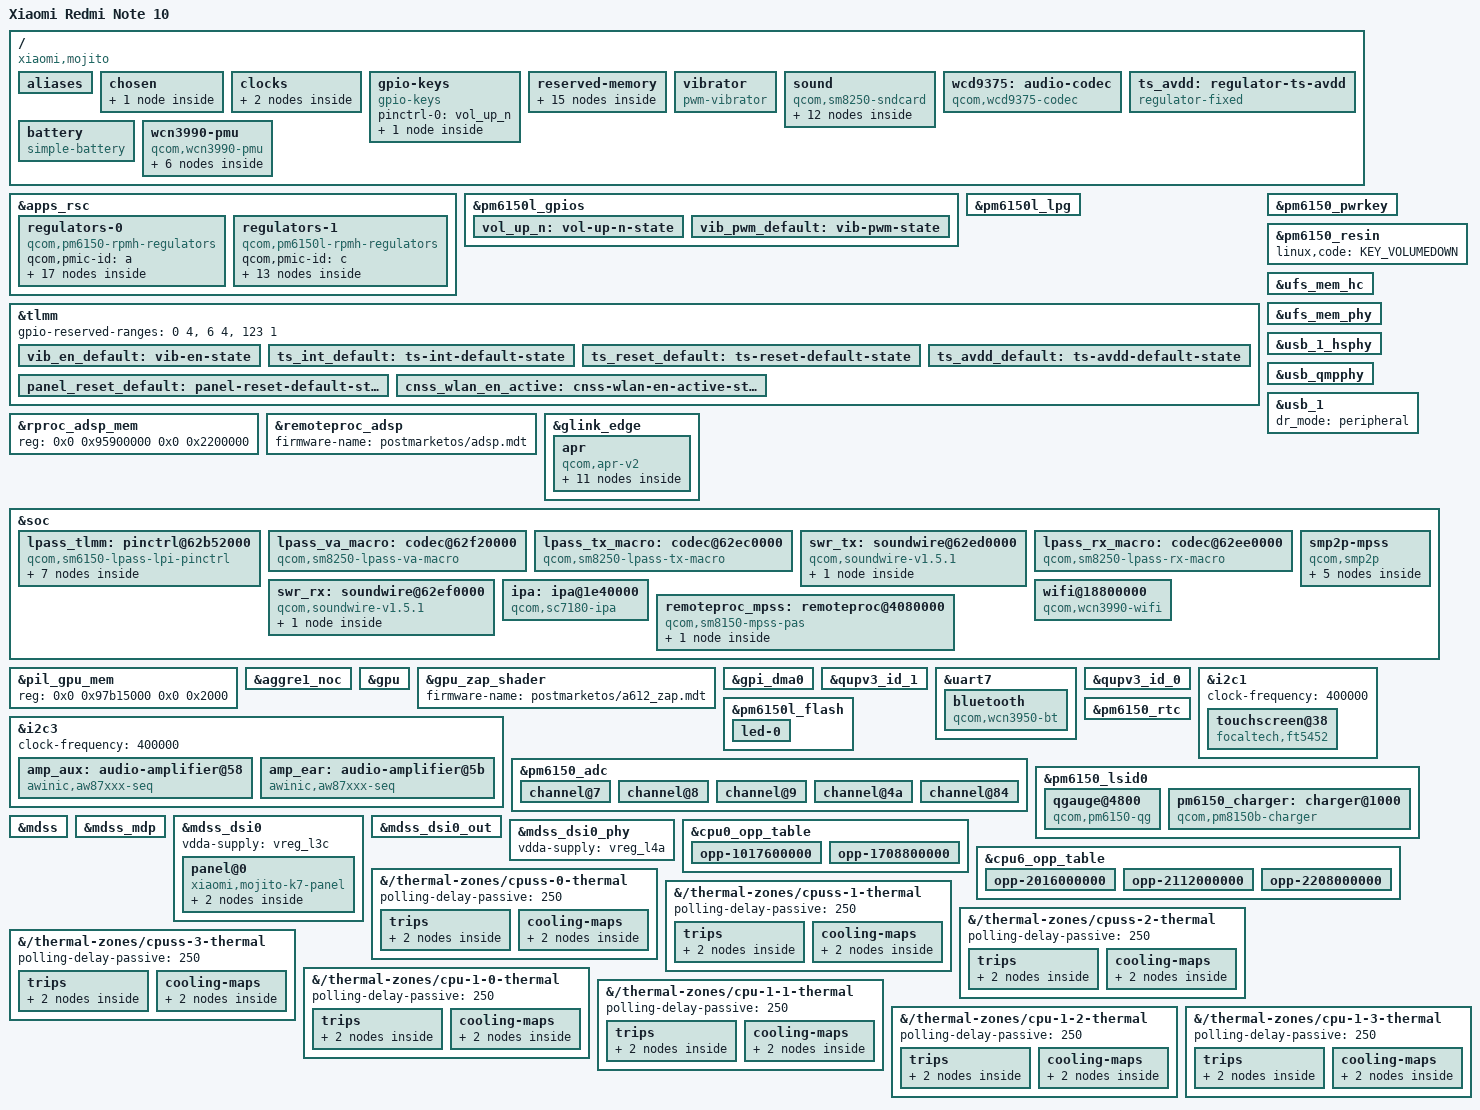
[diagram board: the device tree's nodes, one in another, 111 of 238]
// SPDX-License-Identifier: BSD-3-Clause
/*
 * Xiaomi Redmi Note 10 (mojito / sunny), SM6150 "Talos".
 *
 * Phase 1: boot to a shell. UFS root, USB peripheral (SSH over USB network),
 * buttons, and the bootloader's splash buffer as a simple-framebuffer.
 * Display (DSI panel), GPU, remoteprocs, touch and charging come later.
 *
 * Regulators, supplies and carveouts are taken from the stock downstream
 * device tree of this phone (MIUI V14.0.9.0.SKGMIXM).
 */

/dts-v1/;

#include <dt-bindings/gpio/gpio.h>
#include <dt-bindings/iio/qcom,spmi-vadc.h>
#include <dt-bindings/input/linux-event-codes.h>
#include <dt-bindings/leds/common.h>
#include <dt-bindings/pinctrl/qcom,pmic-gpio.h>
#include <dt-bindings/regulator/qcom,rpmh-regulator.h>
#include <dt-bindings/soc/qcom,apr.h>
#include <dt-bindings/sound/qcom,q6afe.h>
#include <dt-bindings/sound/qcom,q6asm.h>
#include "talos.dtsi"
#include "pm6150.dtsi"
#include "pm6150l.dtsi"

/ {
	model = "Xiaomi Redmi Note 10";
	compatible = "xiaomi,mojito", "qcom,sm6150";
	chassis-type = "handset";

	/*
	 * Matched by the Xiaomi bootloader (ABL) against the DTB in a boot image: msm-id as in the stock
	 * SM6150 DTB, board-id as in the stock IDP overlay. ABL refuses board-id <0 0>.
	 */
	qcom,msm-id = <0x163 0x0>;
	qcom,board-id = <0x22 0x0>;

	aliases {
		serial0 = &uart0;
		serial1 = &uart7;
	};

	chosen {
		#address-cells = <2>;
		#size-cells = <2>;
		ranges;

		/* The bootloader leaves the panel scanning out of cont_splash. */
		framebuffer0: framebuffer@9c000000 {
			compatible = "simple-framebuffer";
			reg = <0x0 0x9c000000 0x0 (1080 * 2400 * 4)>;
			memory-region = <&cont_splash_mem>;
			/*
			 * Deliberately NO power-domains and NO clocks here, although holding MDSS_CORE_GDSC and the display
			 * clocks keeps the splash alive until msm loads. The bootloader leaves its splash pipeline running and
			 * the DPU's CTL stuck in a hardware reset (it never accepts a frame: "hw recovery is not complete for
			 * ctl:1", blue screen); only a power cycle of the display core clears that, and holding the domain on
			 * means it is never cycled. Without the hold, genpd collapses MDSS_CORE_GDSC once nothing uses it
			 * and msm powers it up fresh, which works. Cost: a few seconds of green/black between the splash and
			 * the first real frame. An mdss "resets" line (DISP_CC_MDSS_CORE_BCR) hangs the phone at probe.
			 */
			width = <1080>;
			height = <2400>;
			stride = <(1080 * 4)>;
			format = "a8r8g8b8";
		};
	};

	clocks {
		/* Same SoC crystals as the QCS615 Ride (stock DT: chip_sleep_clk 32 kHz). */
		sleep_clk: sleep-clk {
			compatible = "fixed-clock";
			clock-frequency = <32000>;
			#clock-cells = <0>;
		};

		xo_board_clk: xo-board-clk {
			compatible = "fixed-clock";
			clock-frequency = <38400000>;
			#clock-cells = <0>;
		};
	};

	gpio-keys {
		compatible = "gpio-keys";
		pinctrl-0 = <&vol_up_n>;
		pinctrl-names = "default";

		key-volume-up {
			label = "Volume Up";
			gpios = <&pm6150l_gpios 2 GPIO_ACTIVE_LOW>;
			linux,code = <KEY_VOLUMEUP>;
			debounce-interval = <15>;
			linux,can-disable;
			wakeup-source;
		};
	};

	reserved-memory {
		/* Carveouts present in the stock DT but not (yet) in talos.dtsi. */
		hyp_mem: hyp@85700000 {
			reg = <0x0 0x85700000 0x0 0x600000>;
			no-map;
		};

		/* XBL/AOP firmware; aop-cmd-db@85f20000 (talos.dtsi) sits right after it. */
		xbl_aop_mem: xbl-aop@85e00000 {
			reg = <0x0 0x85e00000 0x0 0x120000>;
			no-map;
		};

		ipa_fw_mem: ipa-fw@97b00000 {
			reg = <0x0 0x97b00000 0x0 0x10000>;
			no-map;
		};

		ipa_gsi_mem: ipa-gsi@97b10000 {
			reg = <0x0 0x97b10000 0x0 0x5000>;
			no-map;
		};

		sec_apps_mem: sec-apps@85fff000 {
			reg = <0x0 0x85fff000 0x0 0x1000>;
			no-map;
		};

		removed_mem: removed@86200000 {
			reg = <0x0 0x86200000 0x0 0x4900000>;
			no-map;
		};

		camera_mem: camera@8ab00000 {
			reg = <0x0 0x8ab00000 0x0 0x500000>;
			no-map;
		};

		mpss_mem: mpss@8b000000 {
			reg = <0x0 0x8b000000 0x0 0x8400000>;
			no-map;
		};

		/* the whole stock wlan_msa_region (2 MB); ath10k assigns it to the modem and WLAN VMIDs itself, like stock icnss and the violet port */
		wlan_msa_mem: wlan-msa@93900000 {
			reg = <0x0 0x93900000 0x0 0x200000>;
			no-map;
		};

		/*
		 * rmtfs shared memory (modem file access through the rmtfs daemon). The vendor tree
		 * allocates it dynamically (qcom,sharedmem-uio reg = <0 0x280000>, guard memory), so this
		 * is a fixed, otherwise unused DRAM range above cdsp-sec (ends 0xa1600000), 0x280000 plus a
		 * guard page on each side. Same placement as the Redmi Note 7 Pro port.
		 */
		rmtfs_mem: rmtfs@a1dff000 {
			compatible = "qcom,rmtfs-mem";
			reg = <0x0 0xa1dff000 0x0 0x282000>;
			no-map;
			qcom,client-id = <1>;
			qcom,use-guard-pages;
			qcom,vmid = <QCOM_SCM_VMID_MSS_MSA>;
		};

		cont_splash_mem: cont-splash@9c000000 {
			reg = <0x0 0x9c000000 0x0 0xf00000>;
			no-map;
		};

		dfps_data_mem: dfps-data@9cf00000 {
			reg = <0x0 0x9cf00000 0x0 0x100000>;
			no-map;
		};

		ramoops@9d800000 {
			compatible = "ramoops";
			reg = <0x0 0x9d800000 0x0 0x400000>;
			/* same layout as the stock kernel, so either can read the other's log */
			record-size = <0x80000>;
			console-size = <0x100000>;
			pmsg-size = <0x200000>;
		};

		qseecom_mem: qseecom@9e400000 {
			reg = <0x0 0x9e400000 0x0 0x1400000>;
			no-map;
		};

		cdsp_sec_mem: cdsp-sec@9f800000 {
			reg = <0x0 0x9f800000 0x0 0x1e00000>;
			no-map;
		};
	};
};

&apps_rsc {
	regulators-0 {
		compatible = "qcom,pm6150-rpmh-regulators";
		qcom,pmic-id = "a";

		vreg_l1a: ldo1 {
			regulator-min-microvolt = <1200000>;
			regulator-max-microvolt = <1252000>;
			regulator-initial-mode = <RPMH_REGULATOR_MODE_HPM>;
		};

		vreg_l2a: ldo2 {
			regulator-min-microvolt = <1000000>;
			regulator-max-microvolt = <1050000>;
			regulator-initial-mode = <RPMH_REGULATOR_MODE_HPM>;
		};

		vreg_l3a: ldo3 {
			regulator-min-microvolt = <1000000>;
			regulator-max-microvolt = <1060000>;
			regulator-initial-mode = <RPMH_REGULATOR_MODE_HPM>;
		};

		vreg_l4a: ldo4 {
			regulator-min-microvolt = <875000>;
			regulator-max-microvolt = <975000>;
			regulator-initial-mode = <RPMH_REGULATOR_MODE_HPM>;
		};

		vreg_l5a: ldo5 {
			regulator-min-microvolt = <2500000>;
			regulator-max-microvolt = <2970000>;
			regulator-initial-mode = <RPMH_REGULATOR_MODE_HPM>;
		};

		vreg_l6a: ldo6 {
			regulator-min-microvolt = <600000>;
			regulator-max-microvolt = <650000>;
			regulator-initial-mode = <RPMH_REGULATOR_MODE_HPM>;
		};

		vreg_l9a: ldo9 {
			regulator-min-microvolt = <400000>;
			regulator-max-microvolt = <728000>;
			regulator-initial-mode = <RPMH_REGULATOR_MODE_HPM>;
		};

		/*
		 * 1.8 V I/O for the WCN3990 (Wi-Fi/Bluetooth), always on in the stock tree; nothing in
		 * Linux votes for it, and without it the WLFW host capability request fails (QMI 90).
		 */
		vreg_l10a: ldo10 {
			regulator-min-microvolt = <1800000>;
			regulator-max-microvolt = <1829000>;
			regulator-initial-mode = <RPMH_REGULATOR_MODE_HPM>;
		};

		vreg_l11a: ldo11 {
			regulator-min-microvolt = <1800000>;
			regulator-max-microvolt = <1890000>;
			regulator-initial-mode = <RPMH_REGULATOR_MODE_HPM>;
		};

		vreg_l12a: ldo12 {
			regulator-min-microvolt = <1800000>;
			regulator-max-microvolt = <1950000>;
			regulator-initial-mode = <RPMH_REGULATOR_MODE_HPM>;
		};

		vreg_l13a: ldo13 {
			regulator-min-microvolt = <1800000>;
			regulator-max-microvolt = <1900000>;
			regulator-initial-mode = <RPMH_REGULATOR_MODE_HPM>;
		};

		vreg_l14a: ldo14 {
			regulator-min-microvolt = <1800000>;
			regulator-max-microvolt = <1850000>;
			regulator-initial-mode = <RPMH_REGULATOR_MODE_HPM>;
		};

		vreg_l15a: ldo15 {
			regulator-min-microvolt = <1800000>;
			regulator-max-microvolt = <1900000>;
			regulator-initial-mode = <RPMH_REGULATOR_MODE_HPM>;
		};

		vreg_l16a: ldo16 {
			regulator-min-microvolt = <2430000>;
			regulator-max-microvolt = <2970000>;
			regulator-initial-mode = <RPMH_REGULATOR_MODE_HPM>;
		};

		vreg_l17a: ldo17 {
			regulator-min-microvolt = <3000000>;
			regulator-max-microvolt = <3230000>;
			regulator-initial-mode = <RPMH_REGULATOR_MODE_HPM>;
		};

		vreg_l18a: ldo18 {
			regulator-min-microvolt = <3000000>;
			regulator-max-microvolt = <3008000>;
			regulator-initial-mode = <RPMH_REGULATOR_MODE_HPM>;
		};

		vreg_l19a: ldo19 {
			regulator-min-microvolt = <2700000>;
			regulator-max-microvolt = <3008000>;
			regulator-initial-mode = <RPMH_REGULATOR_MODE_HPM>;
		};
	};

	regulators-1 {
		compatible = "qcom,pm6150l-rpmh-regulators";
		qcom,pmic-id = "c";

		/* WCD937x mic bias (stock: cdc-vdd-mic-bias-supply = pm6150l_bob) */
		vreg_bob: bob {
			regulator-min-microvolt = <3296000>;
			regulator-max-microvolt = <3960000>;
			regulator-initial-mode = <RPMH_REGULATOR_MODE_AUTO>;
		};

		vreg_s8c: smps8 {
			regulator-min-microvolt = <1200000>;
			regulator-max-microvolt = <1400000>;
			regulator-initial-mode = <RPMH_REGULATOR_MODE_HPM>;
		};

		vreg_l1c: ldo1 {
			regulator-min-microvolt = <1800000>;
			regulator-max-microvolt = <1900000>;
			regulator-initial-mode = <RPMH_REGULATOR_MODE_HPM>;
		};

		vreg_l2c: ldo2 {
			regulator-min-microvolt = <1304000>;
			regulator-max-microvolt = <1304000>;
			regulator-initial-mode = <RPMH_REGULATOR_MODE_HPM>;
		};

		vreg_l3c: ldo3 {
			regulator-min-microvolt = <1232000>;
			regulator-max-microvolt = <1260000>;
			regulator-initial-mode = <RPMH_REGULATOR_MODE_HPM>;
		};

		vreg_l4c: ldo4 {
			regulator-min-microvolt = <1650000>;
			regulator-max-microvolt = <2950000>;
			regulator-initial-mode = <RPMH_REGULATOR_MODE_HPM>;
		};

		vreg_l5c: ldo5 {
			regulator-min-microvolt = <1650000>;
			regulator-max-microvolt = <2950000>;
			regulator-initial-mode = <RPMH_REGULATOR_MODE_HPM>;
		};

		vreg_l6c: ldo6 {
			regulator-min-microvolt = <1650000>;
			regulator-max-microvolt = <3100000>;
			regulator-initial-mode = <RPMH_REGULATOR_MODE_HPM>;
		};

		vreg_l7c: ldo7 {
			regulator-min-microvolt = <3000000>;
			regulator-max-microvolt = <3312000>;
			regulator-initial-mode = <RPMH_REGULATOR_MODE_HPM>;
		};

		vreg_l8c: ldo8 {
			regulator-min-microvolt = <1800000>;
			regulator-max-microvolt = <1900000>;
			regulator-initial-mode = <RPMH_REGULATOR_MODE_HPM>;
		};

		vreg_l9c: ldo9 {
			regulator-min-microvolt = <2950000>;
			regulator-max-microvolt = <3312000>;
			regulator-initial-mode = <RPMH_REGULATOR_MODE_HPM>;
		};

		vreg_l10c: ldo10 {
			regulator-min-microvolt = <3200000>;
			regulator-max-microvolt = <3312000>;
			regulator-initial-mode = <RPMH_REGULATOR_MODE_HPM>;
		};

		vreg_l11c: ldo11 {
			regulator-min-microvolt = <2950000>;
			regulator-max-microvolt = <3312000>;
			regulator-initial-mode = <RPMH_REGULATOR_MODE_HPM>;
		};
	};
};

/* stock: the volume-up key and the vibrator PWM are on the PM6150L, not the PM6150 */
&pm6150l_gpios {
	vol_up_n: vol-up-n-state {
		pins = "gpio2";
		function = "normal";
		power-source = <0>;
		bias-pull-up;
		input-enable;
	};

	vib_pwm_default: vib-pwm-state {
		pins = "gpio6";
		function = "func1";
		power-source = <0>;
		qcom,drive-strength = <3>;
		drive-push-pull;
		bias-disable;
		output-low;
	};
};

/* PWM channel at SPMI 0xbc00 (index 3) drives the vibration motor */
&pm6150l_lpg {
	status = "okay";
};

&tlmm {
	vib_en_default: vib-en-state {
		pins = "gpio112";
		function = "gpio";
		drive-strength = <2>;
		bias-disable;
		output-low;
	};
};

/ {
	/* stock "qcom,lct-pwm-vibrator": 50 us period, enable on TLMM 112 */
	vibrator {
		compatible = "pwm-vibrator";
		pinctrl-names = "default";
		pinctrl-0 = <&vib_en_default>, <&vib_pwm_default>;
		pwms = <&pm6150l_lpg 3 50000>;
		pwm-names = "enable";
		enable-gpios = <&tlmm 112 GPIO_ACTIVE_HIGH>;
	};
};

&pm6150_pwrkey {
	status = "okay";
};

&pm6150_resin {
	linux,code = <KEY_VOLUMEDOWN>;
	status = "okay";
};


&ufs_mem_hc {
	vcc-supply = <&vreg_l11c>;
	vcc-max-microamp = <600000>;
	vccq2-supply = <&vreg_l12a>;
	vccq2-max-microamp = <600000>;

	status = "okay";
};

&ufs_mem_phy {
	vdda-phy-supply = <&vreg_l4a>;
	vdda-pll-supply = <&vreg_l11a>;

	status = "okay";
};

&usb_1_hsphy {
	vdd-supply = <&vreg_l4a>;
	vdda-pll-supply = <&vreg_l11a>;
	vdda-phy-dpdm-supply = <&vreg_l17a>;

	status = "okay";
};

&usb_qmpphy {
	vdda-phy-supply = <&vreg_l4a>;
	vdda-pll-supply = <&vreg_l11a>;

	status = "okay";
};

&usb_1 {
	/* No Type-C role switching yet: stay a USB gadget for SSH over USB. */
	dr_mode = "peripheral";

	status = "okay";
};

/* Xiaomi's firmware layout differs from the QCS615 Ride's. */
&rproc_adsp_mem {
	reg = <0x0 0x95900000 0x0 0x2200000>;
};

/*
 * ADSP (audio, sensors). Stock firmware from the phone's modem partition, signed for this device.
 * It speaks legacy APR, not AudioReach, so talos.dtsi's gpr/q6apm children stay unused (the
 * firmware never opens "adsp_apps"); APR nodes come with the sound card.
 */
&remoteproc_adsp {
	firmware-name = "postmarketos/adsp.mdt";
	status = "okay";
};

/*
 * Audio services on the ADSP: legacy APR (the firmware offers "apr_audio_svc"), replacing talos.dtsi's
 * AudioReach gpr node, which this firmware never answers. Layout as in the Redmi Note 7 Pro port, with
 * the protection domains declared (pd-mapper works here, patch 0011). ASM shared memory goes through
 * SMMU stream 0x1721 (stock msm_audio_ion), which needs patch 0014 (hypervisor-owned context banks).
 */
/delete-node/ &gpr;

&glink_edge {
	apr {
		compatible = "qcom,apr-v2";
		qcom,glink-channels = "apr_audio_svc";
		qcom,domain = <APR_DOMAIN_ADSP>;
		#address-cells = <1>;
		#size-cells = <0>;

		service@3 {
			compatible = "qcom,q6core";
			reg = <APR_SVC_ADSP_CORE>;
			qcom,protection-domain = "avs/audio", "msm/adsp/audio_pd";
		};

		q6afe: service@4 {
			compatible = "qcom,q6afe";
			reg = <APR_SVC_AFE>;
			qcom,protection-domain = "avs/audio", "msm/adsp/audio_pd";

			q6afedai: dais {
				compatible = "qcom,q6afe-dais";
				#address-cells = <1>;
				#size-cells = <0>;
				#sound-dai-cells = <1>;
			};

			q6afecc: clock-controller {
				compatible = "qcom,q6afe-clocks";
				#clock-cells = <2>;
			};
		};

		q6asm: service@7 {
			compatible = "qcom,q6asm";
			reg = <APR_SVC_ASM>;
			qcom,protection-domain = "avs/audio", "msm/adsp/audio_pd";

			q6asmdai: dais {
				compatible = "qcom,q6asm-dais";
				#address-cells = <1>;
				#size-cells = <0>;
				#sound-dai-cells = <1>;
				iommus = <&apps_smmu 0x1721 0x0>;

				dai@0 {
					reg = <MSM_FRONTEND_DAI_MULTIMEDIA1>;
				};

				dai@1 {
					reg = <MSM_FRONTEND_DAI_MULTIMEDIA2>;
				};

				dai@2 {
					reg = <MSM_FRONTEND_DAI_MULTIMEDIA3>;
				};
			};
		};

		q6adm: service@8 {
			compatible = "qcom,q6adm";
			reg = <APR_SVC_ADM>;
			qcom,protection-domain = "avs/audio", "msm/adsp/audio_pd";

			q6routing: routing {
				compatible = "qcom,q6adm-routing";
				#sound-dai-cells = <0>;
			};
		};
	};
};

/*
 * Audio: LPASS LPI pins + VA/TX/RX macros + SoundWire + WCD9375 (stock "bolero" layout).
 * Sources: stock mojito DT (pins, IRQs, supplies, mic bias), the SM7150 ports that have the same LPASS
 * block and codec (Xiaomi surya / Mi 9T fixes: LPI mux, reset pin as gpio, no dcodec vote, TX port map),
 * and the violet notes (APR, not AudioReach). Untested on this phone (2026-11-27).
 */
&soc {
	/* stock lpi_pinctrl: 0x62b40000 + 0x1000 per pin, gpio18..31 = these pins 0..13 */
	lpass_tlmm: pinctrl@62b52000 {
		compatible = "qcom,sm6150-lpass-lpi-pinctrl";
		reg = <0x0 0x62b52000 0x0 0xe000>;
		/* stock: lpass_core_hw_vote (audio-ref-clk src 9) = AFE LPASS core HW vote */
		clocks = <&q6afecc LPASS_HW_MACRO_VOTE LPASS_CLK_ATTRIBUTE_COUPLE_NO>;
		clock-names = "core";
		gpio-controller;
		#gpio-cells = <2>;
		gpio-ranges = <&lpass_tlmm 0 0 14>;

		tx_swr_active: tx-swr-active-state {
			clk-pins {
				pins = "gpio0";
				function = "swr_tx_clk";
				drive-strength = <8>;
				bias-bus-hold;
			};

			data-pins {
				pins = "gpio1", "gpio2";
				function = "swr_tx_data";
				drive-strength = <8>;
				bias-bus-hold;
			};
		};

		rx_swr_active: rx-swr-active-state {
			clk-pins {
				pins = "gpio3";
				function = "swr_rx_clk";
				drive-strength = <8>;
				bias-bus-hold;
			};

			data-pins {
				pins = "gpio4", "gpio5";
				function = "swr_rx_data";
				drive-strength = <8>;
				bias-bus-hold;
			};
		};

		/* stock msm_cdc_pinctrl@24 (qcom,lpi-gpios): WCD937x reset; plain gpio, level owned by the driver */
		wcd_reset_default: wcd-reset-default-state {
			pins = "gpio6";
			function = "gpio";
			drive-strength = <16>;
			bias-disable;
		};
	};

	/* fsgen master for TX/RX; shares the TX core mclk; only the "macro" vote (no dcodec in this firmware) */
	lpass_va_macro: codec@62f20000 {
		compatible = "qcom,sm8250-lpass-va-macro";
		reg = <0x0 0x62f20000 0x0 0x1000>;
		clocks = <&q6afecc LPASS_CLK_ID_TX_CORE_MCLK LPASS_CLK_ATTRIBUTE_COUPLE_NO>,
			 <&q6afecc LPASS_HW_MACRO_VOTE LPASS_CLK_ATTRIBUTE_COUPLE_NO>;
		clock-names = "mclk", "macro";
		#clock-cells = <0>;
		clock-output-names = "fsgen";
		#sound-dai-cells = <1>;
	};

	lpass_tx_macro: codec@62ec0000 {
		compatible = "qcom,sm8250-lpass-tx-macro";
		reg = <0x0 0x62ec0000 0x0 0x1000>;
		pinctrl-names = "default";
		pinctrl-0 = <&tx_swr_active>;
		clocks = <&q6afecc LPASS_CLK_ID_TX_CORE_MCLK LPASS_CLK_ATTRIBUTE_COUPLE_NO>,
			 <&q6afecc LPASS_CLK_ID_TX_CORE_NPL_MCLK LPASS_CLK_ATTRIBUTE_COUPLE_NO>,
			 <&q6afecc LPASS_HW_MACRO_VOTE LPASS_CLK_ATTRIBUTE_COUPLE_NO>,
			 <&lpass_va_macro>;
		clock-names = "mclk", "npl", "macro", "fsgen";
		#clock-cells = <0>;
		clock-output-names = "lpass-tx-mclk";
		#sound-dai-cells = <1>;
	};

	/* stock tx_swr_master: swrm-io-base 0x62ed0000, SPI 137 + wake SPI 623 (= PDC pin 108) */
	swr_tx: soundwire@62ed0000 {
		compatible = "qcom,soundwire-v1.5.1";
		reg = <0x0 0x62ed0000 0x0 0x2000>;
		interrupts-extended = <&intc GIC_SPI 137 IRQ_TYPE_LEVEL_HIGH 0>,
				      <&pdc 108 IRQ_TYPE_LEVEL_HIGH>;
		interrupt-names = "core", "wakeup";
		clocks = <&lpass_tx_macro>;
		clock-names = "iface";
		label = "TX";

		/* hardware: 6 in + 1 out (port 1 = PCM_OUT1); one byte per port, 7 ports.
		 * Timing = stock tx_frame_params_superset (si 3, lane 0); the SM7150 "perf" values gave zeros. */
		qcom,din-ports = <6>;
		qcom,dout-ports = <1>;
		qcom,ports-sinterval-low =	/bits/ 8 <0xff 0x03 0x03 0x03 0x03 0xff 0xff>;
		qcom,ports-offset1 =		/bits/ 8 <0xff 0x01 0x02 0x01 0x00 0xff 0xff>;
		qcom,ports-offset2 =		/bits/ 8 <0xff 0x00 0x00 0x00 0x00 0xff 0xff>;
		qcom,ports-block-pack-mode =	/bits/ 8 <0xff 0xff 0xff 0xff 0xff 0xff 0xff>;
		qcom,ports-hstart =		/bits/ 8 <0xff 0xff 0xff 0xff 0xff 0xff 0xff>;
		qcom,ports-hstop =		/bits/ 8 <0xff 0xff 0xff 0xff 0xff 0xff 0xff>;
		qcom,ports-word-length =	/bits/ 8 <0xff 0xff 0xff 0xff 0xff 0xff 0xff>;
		qcom,ports-block-group-count =	/bits/ 8 <0xff 0xff 0xff 0xff 0xff 0xff 0xff>;
		qcom,ports-lane-control =	/bits/ 8 <0xff 0x00 0x00 0x00 0x00 0xff 0xff>;

		#sound-dai-cells = <1>;
		#address-cells = <2>;
		#size-cells = <0>;

		wcd_tx: codec@0,3 {
			compatible = "sdw20217010a00";
			reg = <0 3>;
			/* WCD937x TX ports ADC1, ADC2/3, DMIC0-3+MBHC, DMIC4-7 -> SWR ports 2, 2, 3, 4 (port 1 = PCM_OUT1) */
			qcom,tx-port-mapping = <2 2 3 4>;
		};
	};

	lpass_rx_macro: codec@62ee0000 {
		compatible = "qcom,sm8250-lpass-rx-macro";
		reg = <0x0 0x62ee0000 0x0 0x1000>;
		pinctrl-names = "default";
		pinctrl-0 = <&rx_swr_active>;
		clocks = <&q6afecc LPASS_CLK_ID_RX_CORE_MCLK LPASS_CLK_ATTRIBUTE_COUPLE_NO>,
			 <&q6afecc LPASS_CLK_ID_RX_CORE_NPL_MCLK LPASS_CLK_ATTRIBUTE_COUPLE_NO>,
			 <&q6afecc LPASS_HW_MACRO_VOTE LPASS_CLK_ATTRIBUTE_COUPLE_NO>,
			 <&lpass_va_macro>;
		clock-names = "mclk", "npl", "macro", "fsgen";
		#clock-cells = <0>;
		clock-output-names = "lpass-rx-mclk";
		#sound-dai-cells = <1>;
	};

	/* stock rx_swr_master: 0x62ef0000, SPI 138 */
	swr_rx: soundwire@62ef0000 {
		compatible = "qcom,soundwire-v1.5.1";
		reg = <0x0 0x62ef0000 0x0 0x2000>;
		interrupts = <GIC_SPI 138 IRQ_TYPE_LEVEL_HIGH 0>;
		clocks = <&lpass_rx_macro>;
		clock-names = "iface";
		label = "RX";

		/* hardware: 1 in + 6 out; one byte per port, 7 ports (short tables clash the bus) */
		qcom,din-ports = <1>;
		qcom,dout-ports = <6>;
		qcom,ports-sinterval-low =	/bits/ 8 <0x03 0x1f 0x1f 0x07 0x00 0xff 0xff>;
		qcom,ports-offset1 =		/bits/ 8 <0x00 0x00 0x0b 0x01 0x00 0xff 0xff>;
		qcom,ports-offset2 =		/bits/ 8 <0x00 0x00 0x0b 0x00 0x00 0xff 0xff>;
		qcom,ports-hstart =		/bits/ 8 <0xff 0x03 0xff 0xff 0xff 0xff 0xff>;
		qcom,ports-hstop =		/bits/ 8 <0xff 0x06 0xff 0xff 0xff 0xff 0xff>;
		qcom,ports-word-length =	/bits/ 8 <0x01 0x07 0x04 0xff 0xff 0xff 0xff>;
		qcom,ports-block-pack-mode =	/bits/ 8 <0xff 0x00 0x01 0xff 0xff 0xff 0xff>;
		qcom,ports-lane-control =	/bits/ 8 <0x01 0x00 0x00 0x00 0x00 0xff 0xff>;
		qcom,ports-block-group-count =	/bits/ 8 <0xff 0xff 0xff 0xff 0x00 0xff 0xff>;

		#sound-dai-cells = <1>;
		#address-cells = <2>;
		#size-cells = <0>;

		wcd_rx: codec@0,4 {
			compatible = "sdw20217010a00";
			reg = <0 4>;
			qcom,rx-port-mapping = <1 2 3 4 5>;
		};
	};


};

/ {
	sound {
		compatible = "qcom,sm8250-sndcard";
		model = "Xiaomi Redmi Note 10";

		/* stock mics: amic1 = ADC1 (main), amic2/amic3 = ADC2 via ADC2 MUX INP2/INP3 */
		aux-devs = <&amp_aux>, <&amp_ear>;

		audio-routing =
			"AUX Amp IN", "AUX",
			"EAR Amp IN", "EAR",
			"AMIC1", "MIC BIAS1",
			"AMIC2", "MIC BIAS2",
			"AMIC3", "MIC BIAS3",
			"TX SWR_ADC0", "ADC1_OUTPUT",
			"TX SWR_ADC1", "ADC2_OUTPUT",
			"TX SWR_ADC2", "ADC3_OUTPUT";

		mm1-dai-link {
			link-name = "MultiMedia1";

			cpu {
				sound-dai = <&q6asmdai MSM_FRONTEND_DAI_MULTIMEDIA1>;
			};
		};

		mm2-dai-link {
			link-name = "MultiMedia2";

			cpu {
				sound-dai = <&q6asmdai MSM_FRONTEND_DAI_MULTIMEDIA2>;
			};
		};

		/* headphones (and earpiece/speaker later, via WCD937x EAR/AUX + the AW87xxx amps) */
		wcd-playback-dai-link {
			link-name = "WCD Playback";

			cpu {
				sound-dai = <&q6afedai RX_CODEC_DMA_RX_0>;
			};

			platform {
				sound-dai = <&q6routing>;
			};

			codec {
				sound-dai = <&wcd9375 0>, <&swr_rx 0>, <&lpass_rx_macro 0>;
			};
		};

		wcd-capture-dai-link {
			link-name = "WCD Capture";

			cpu {
				sound-dai = <&q6afedai TX_CODEC_DMA_TX_3>;
			};

			platform {
				sound-dai = <&q6routing>;
			};

			codec {
				/* swr_tx has one dout port, so DAI 0 is playback-only; capture DAIs start at 1.
				 * With DAI 0 no master data port is set up and the mic records zeros. */
				sound-dai = <&wcd9375 1>, <&swr_tx 1>, <&lpass_tx_macro 0>;
			};
		};
	};
	wcd9375: audio-codec {
		compatible = "qcom,wcd9375-codec";
		pinctrl-names = "default";
		pinctrl-0 = <&wcd_reset_default>;
		reset-gpios = <&lpass_tlmm 6 GPIO_ACTIVE_LOW>;

		/* stock: buck = pm6150_l15, rxtx/px = pm6150_l10, mic bias = pm6150l_bob, micbias 2.7 V */
		vdd-buck-supply = <&vreg_l15a>;
		vdd-rxtx-supply = <&vreg_l10a>;
		vdd-px-supply = <&vreg_l10a>;
		vdd-mic-bias-supply = <&vreg_bob>;

		qcom,micbias1-microvolt = <2700000>;
		qcom,micbias2-microvolt = <2700000>;
		qcom,micbias3-microvolt = <2700000>;
		qcom,micbias4-microvolt = <2700000>;

		qcom,rx-device = <&wcd_rx>;
		qcom,tx-device = <&wcd_tx>;

		#sound-dai-cells = <1>;
	};
};

&pil_gpu_mem {
	reg = <0x0 0x97b15000 0x0 0x2000>;
};

/*
 * Hardware hazards found on this SoC family. Both were also hit by the Redmi Note 7 Pro port
 * (github.com/VipinVIP/violet-sm6150-mainline); the TLMM one needs more reservations on this phone.
 */

/*
 * TLMM: eight GPIOs are owned by the secure world and must not be read: gpio0-3 (WEST tile) and gpio6-9
 * (EAST tile), probably the first two QUP serial engines kept for something like a fingerprint sensor or a
 * secure element. A read of gpio0 or gpio1 hangs the CPU; a read of gpio2, 3 or 6-9 raises a synchronous
 * external abort. The pin controller reads the control register of every valid line when it registers the
 * gpio chip, so a single one of these being valid kills the probe (the oops is in msm_gpio_get_direction).
 *
 * Found by reading every pin through /dev/mem from userspace, one child process per pin, and recording the
 * child's exit status (a child killed by SIGBUS is an abort, a child that never returns is a wedge); the
 * other 115 pins read back plausible register values, and the kernel then registered the chip and dumped all
 * of them. The Redmi Note 7 Pro port reserves only <0 4>, which is not enough here (gpio6 aborts).
 *
 * gpio123 is UFS_RESET (its register is at west tile + 0x9f000, outside the 0x1000 * id pattern); it was
 * not scanned and nothing here uses it, so it stays reserved as a precaution.
 */
&tlmm {
	gpio-reserved-ranges = <0 4>, <6 4>, <123 1>;
};

/* aggre1_noc QoS writes hang the CPU: leave it unclocked so they are skipped. */
&aggre1_noc {
	/delete-property/ clocks;
};

/*
 * Adreno 612. Needs msm.ko loaded with separate_gpu_kms=1 while no display subsystem is enabled (the
 * display stays on simpledrm), which gives a render-only DRM device. Firmware: a630_sqe.fw and a612_rgmu.bin
 * are found through /lib/firmware/qcom (symlinks to /lib/firmware/postmarketos/, left by the downstream
 * install). The zap shader is signed for this phone by the vendor, so it must come from the stock firmware:
 * the split a612_zap.mdt + .b00-.b02 already in /lib/firmware/postmarketos/.
 */
&gpu {
	status = "okay";
};

&gpu_zap_shader {
	firmware-name = "postmarketos/a612_zap.mdt";
};

/*
 * Touchscreen: FocalTech FT5452 on i2c1 (QUP0 SE1, gpio4/gpio5) at 0x38. Identified by reading its chip-id
 * registers from userspace: 0xa3 = 0x54 and 0x9f = 0x52 (chip id 0x5452); nothing answers at 0x48, so the
 * Himax variant listed in the stock tree is not fitted. The driver is edt-ft5x06 (CONFIG_TOUCHSCREEN_EDT_FT5X06).
 * Power: the analog supply is a plain GPIO (gpio96) in the stock tree, so it is a fixed regulator here, and the
 * I/O rail is pm6150 ldo13 (1.8 V). Reset is gpio88 (active low), the interrupt gpio89 (falling edge). All of
 * these pins are outside the secure-world set reserved above.
 */
&gpi_dma0 {
	status = "okay";
};

&qupv3_id_1 {
	status = "okay";
};

/* WCN3950 Bluetooth on QUP SE7 (UART7, gpio10-13), the stock qcom,qup_uart@0xa8c000 */
&uart7 {
	status = "okay";

	bluetooth {
		compatible = "qcom,wcn3950-bt";

		vddio-supply = <&vreg_pmu_io>;
		vddxo-supply = <&vreg_pmu_xo>;
		vddrf-supply = <&vreg_pmu_rf>;
		vddch0-supply = <&vreg_pmu_ch0>;
		swctrl-gpios = <&tlmm 102 GPIO_ACTIVE_HIGH>;

		max-speed = <3200000>;
	};
};

&qupv3_id_0 {
	status = "okay";
};

&tlmm {
	ts_int_default: ts-int-default-state {
		pins = "gpio89";
		function = "gpio";
		drive-strength = <2>;
		bias-pull-up;
		input-enable;
	};

	ts_reset_default: ts-reset-default-state {
		pins = "gpio88";
		function = "gpio";
		drive-strength = <2>;
		bias-disable;
	};

	ts_avdd_default: ts-avdd-default-state {
		pins = "gpio96";
		function = "gpio";
		drive-strength = <2>;
		bias-disable;
	};
};

/ {
	ts_avdd: regulator-ts-avdd {
		compatible = "regulator-fixed";
		regulator-name = "ts_avdd";
		/* the stock tree gives no voltage for this GPIO-switched rail; fixed regulators need a nominal one */
		regulator-min-microvolt = <3300000>;
		regulator-max-microvolt = <3300000>;
		gpio = <&tlmm 96 GPIO_ACTIVE_HIGH>;
		enable-active-high;
		pinctrl-0 = <&ts_avdd_default>;
		pinctrl-names = "default";
	};
};

&i2c1 {
	clock-frequency = <400000>;
	status = "okay";

	touchscreen@38 {
		compatible = "focaltech,ft5452";
		reg = <0x38>;
		interrupt-parent = <&tlmm>;
		interrupts = <89 IRQ_TYPE_EDGE_FALLING>;
		reset-gpios = <&tlmm 88 GPIO_ACTIVE_LOW>;
		vcc-supply = <&ts_avdd>;
		iovcc-supply = <&vreg_l13a>;
		pinctrl-0 = <&ts_int_default>, <&ts_reset_default>;
		pinctrl-names = "default";
		touchscreen-size-x = <1080>;
		touchscreen-size-y = <2400>;
	};
};

/*
 * i2c3 (0x88c000; the vendor kernel calls it i2c2) carries the two Awinic
 * aw87xxx speaker amplifiers (0x58, 0x5b), the FSA4480 USB-C audio switch
 * (0x43), the BQ2597x charge pump (0x65) and the camera regulator (0x28).
 * No client drivers are bound yet: enabling the bus lets /dev/i2c-N probe them.
 */
&i2c3 {
	clock-frequency = <400000>;
	status = "okay";

	/*
	 * Awinic AW87xxx amplifiers, register tables from the stock playback trace (Android powers
	 * both for media). 0x58 (id 0x59, stock pa-channel 1) is fed by the WCD937x AUX output and has
	 * no reset line; 0x5b (id 0x5a, pa-channel 0, reset = gpio 83) by EAR. The bottom speaker
	 * played with both enabled (2026-11-27); 0x58 alone stayed silent.
	 */
	amp_aux: audio-amplifier@58 {
		compatible = "awinic,aw87xxx-seq";
		reg = <0x58>;
		sound-name-prefix = "AUX Amp";
		awinic,on-sequence = /bits/ 8 <0x70 0x80  0x01 0x00  0x01 0x00
			0x02 0x0c  0x03 0x05  0x04 0x05  0x05 0x0c  0x06 0x07  0x07 0xae  0x08 0x09
			0x09 0x08  0x0a 0x4b  0x61 0xbb  0x62 0x80  0x63 0x29  0x64 0x58  0x65 0xcd
			0x66 0x3c  0x67 0x3f  0x68 0x3f  0x69 0xdf  0x01 0x0d>;
		awinic,off-sequence = /bits/ 8 <0x01 0x00>;
	};

	amp_ear: audio-amplifier@5b {
		compatible = "awinic,aw87xxx-seq";
		reg = <0x5b>;
		reset-gpios = <&tlmm 83 GPIO_ACTIVE_LOW>;
		sound-name-prefix = "EAR Amp";
		awinic,on-sequence = /bits/ 8 <0x78 0x39  0x79 0xe5  0x77 0xc4  0x77 0xc4
			0x78 0x7a  0x79 0x6c  0x77 0x81  0x66 0x70  0x58 0x01  0x02 0x49  0x03 0x0a
			0x04 0x00  0x05 0x08  0x06 0x0c  0x07 0x4b  0x08 0x8e  0x09 0x0b  0x0a 0x08
			0x0b 0x7b  0x0c 0x03  0x0d 0x77  0x0e 0x7a  0x0f 0x42  0x10 0x58  0x60 0x6a
			0x61 0x12  0x62 0xb5  0x63 0xfa  0x64 0xd5  0x65 0x07  0x67 0x28  0x68 0x35
			0x69 0x80  0x70 0x1c  0x71 0x9c  0x72 0x33  0x73 0x40  0x74 0x0c  0x01 0x78>;
		awinic,off-sequence = /bits/ 8 <0x01 0x00>;
	};
};

/* Camera flash LED (PM6150L). Vendor limits: torch 500 mA, flash 1.5 A, 1.28 s. */
&pm6150l_flash {
	status = "okay";

	led-0 {
		function = LED_FUNCTION_FLASH;
		color = <LED_COLOR_ID_WHITE>;
		led-sources = <1>;
		led-max-microamp = <300000>;
		flash-max-microamp = <1000000>;
		flash-max-timeout-us = <1280000>;
	};
};

/*
 * The RTC is read-only (the vendor tree sets qcom,qpnp-rtc-write = 0): no
 * allow-set-time, so the kernel only reads the time the firmware keeps.
 */
&pm6150_rtc {
	status = "okay";
};

/*
 * PM6150 ADC channels for the battery and charger, copied from the stock vadc@3100 node (same
 * channel numbers and pre-scaling). bat_therm (0x4a, 100k pull-up) needs kernel patch 0009: without
 * it the adc5 table has no entry for the channel and the whole ADC probe fails.
 */
&pm6150_adc {
	channel@7 {
		reg = <ADC5_USB_IN_I>;
		qcom,pre-scaling = <1 1>;
		label = "usb_in_i_uv";
	};

	channel@8 {
		reg = <ADC5_USB_IN_V_16>;
		qcom,pre-scaling = <1 16>;
		label = "usb_in_v_div_16";
	};

	channel@9 {
		reg = <ADC5_CHG_TEMP>;
		qcom,pre-scaling = <1 1>;
		label = "chg_temp";
	};

	channel@4a {
		reg = <ADC5_BAT_THERM_100K_PU>;
		qcom,ratiometric;
		qcom,hw-settle-time = <200>;
		qcom,pre-scaling = <1 1>;
		label = "bat_therm";
	};

	channel@84 {
		reg = <ADC5_VBAT_SNS>;
		qcom,pre-scaling = <1 3>;
		label = "vbat_sns";
	};
};

/*
 * Battery: the stock profile "m305-nvt-5000mah" (qcom,battery-data). Float voltage 4.45 V. The OCV
 * tables are its pc-temp-v1-lut (discharge OCV vs. state of charge at 0/10/25/40/50 C), converted
 * from 100 uV units; the 9..1 % rows are kept, duplicates dropped.
 */
/ {
	battery: battery {
		compatible = "simple-battery";
		device-chemistry = "lithium-ion-polymer";
		voltage-min-design-microvolt = <3400000>;
		voltage-max-design-microvolt = <4450000>; /* cell rating (stock qcom,max-voltage-uv); Android floats up to 4.47 V */
		charge-full-design-microamp-hours = <5000000>;
		constant-charge-current-max-microamp = <2000000>;	/* conservative; vendor uses up to 6 A with the bq2597x pump */
		factory-internal-resistance-micro-ohms = <120000>;
		ocv-capacity-celsius = <0 10 25 40 50>;
		/* 0 C */
		ocv-capacity-table-0 = <4416500 100 4397700 98 4376700 96 4354700 94 4331900 92 4308200 90
			4284300 88 4260200 86 4236000 84 4212300 82 4188900 80 4165900 78
			4143400 76 4121400 74 4100100 72 4079800 70 4059700 68 4039000 66
			4018400 64 3999100 62 3982100 60 3964800 58 3943400 56 3917800 54
			3897200 52 3883700 50 3873100 48 3864800 46 3858300 44 3852400 42
			3846700 40 3841400 38 3836400 36 3831700 34 3827400 32 3823500 30
			3820000 28 3815600 26 3808000 24 3797700 22 3786400 20 3772900 18
			3757700 16 3740000 14 3727200 12 3718500 10 3716400 9 3715200 8
			3711100 7 3698900 6 3662100 5 3612600 4 3549000 3 3461300 2
			3319900 1 3000000 0>;
		/* 10 C */
		ocv-capacity-table-1 = <4426200 100 4407600 98 4388100 96 4368000 94 4346800 92 4324000 90
			4300100 88 4276100 86 4251600 84 4227100 82 4203100 80 4179300 78
			4156200 76 4133400 74 4111400 72 4090700 70 4070700 68 4050900 66
			4031800 64 4012000 62 3988700 60 3961600 58 3937500 56 3917800 54
			3900900 52 3888400 50 3879000 48 3870300 46 3861600 44 3853400 42
			3845800 40 3838500 38 3832000 36 3826500 34 3821600 32 3817000 30
			3813000 28 3808500 26 3801200 24 3790900 22 3779300 20 3766100 18
			3751200 16 3733700 14 3720200 12 3712800 10 3710200 9 3708500 8
			3705200 7 3692800 6 3655900 5 3606900 4 3543800 3 3456400 2
			3315600 1 3000000 0>;
		/* 25 C */
		ocv-capacity-table-2 = <4434100 100 4418300 98 4398600 96 4378800 94 4358300 92 4336700 90
			4313700 88 4289500 86 4265100 84 4240300 82 4215700 80 4191600 78
			4167700 76 4144300 74 4121400 72 4099100 70 4077800 68 4057200 66
			4037500 64 4019300 62 3999300 60 3972600 58 3943400 56 3922700 54
			3907800 52 3895000 50 3883300 48 3872800 46 3862600 44 3852600 42
			3843500 40 3835400 38 3828100 36 3821500 34 3815800 32 3810300 30
			3805100 28 3799900 26 3792800 24 3782900 22 3771500 20 3758900 18
			3744600 16 3727800 14 3714600 12 3707000 10 3705000 9 3703100 8
			3700200 7 3686100 6 3649000 5 3600200 4 3537100 3 3450600 2
			3311300 1 3000000 0>;
		/* 40 C */
		ocv-capacity-table-3 = <4435900 100 4418500 98 4400200 96 4381100 94 4361200 92 4340100 90
			4317600 88 4293600 86 4269200 84 4244600 82 4220000 80 4195900 78
			4172000 76 4148500 74 4125400 72 4102800 70 4081000 68 4060000 66
			4039900 64 4021800 62 4002800 60 3978200 58 3949600 56 3927600 54
			3912000 52 3898600 50 3885400 48 3873200 46 3862200 44 3852300 42
			3843200 40 3834800 38 3826900 36 3819600 34 3812700 32 3806100 30
			3799600 28 3793200 26 3785000 24 3774400 22 3762600 20 3749900 18
			3736000 16 3720000 14 3707300 12 3700400 10 3698200 9 3696600 8
			3693100 7 3676500 6 3639600 5 3591200 4 3528800 3 3442800 2
			3306600 1 3000000 0>;
		/* 50 C */
		ocv-capacity-table-4 = <4437200 100 4419600 98 4401400 96 4382400 94 4362300 92 4341100 90
			4319000 88 4295700 86 4271800 84 4247500 82 4222700 80 4198400 78
			4174100 76 4150200 74 4127000 72 4104300 70 4082600 68 4061700 66
			4041600 64 4023000 62 4004000 60 3980400 58 3952400 56 3929800 54
			3913800 52 3900200 50 3886700 48 3873800 46 3862300 44 3852200 42
			3843000 40 3834400 38 3826500 36 3818900 34 3811700 32 3804500 30
			3796900 28 3789000 26 3779800 24 3768900 22 3756700 20 3743200 18
			3728600 16 3711900 14 3700300 12 3694500 10 3692500 9 3690600 8
			3686200 7 3666700 6 3629400 5 3580600 4 3517600 3 3430700 2
			3291800 1 3000000 0>;
	};
};

&pm6150_lsid0 {
	/*
	 * QGauge (fuel gauge) and its SDAM. Driven read-only by qcom_qg_lite (patch 0010): the bootloader
	 * leaves it measuring; SDAM holds the last saved SOC (0x47) and the learned capacity (0x68).
	 */
	qgauge@4800 {
		compatible = "qcom,pm6150-qg";
		reg = <0x4800>, <0xb600>;
		io-channels = <&pm6150_adc ADC5_BAT_THERM_100K_PU>,
			      <&pm6150_adc ADC5_USB_IN_V_16>;
		io-channel-names = "batt_therm", "usb_in_v";
		monitored-battery = <&battery>;
		power-supplies = <&pm6150_charger>;	/* status comes from the charger while plugged in */
	};

	/*
	 * SMB5 charger (patch 0008). The module is blacklisted in /etc/modprobe.d until it is tested by
	 * hand: it reprograms the input current limit and charging enable.
	 */
	pm6150_charger: charger@1000 {
		compatible = "qcom,pm8150b-charger";
		reg = <0x1000>;

		interrupts = <0x0 0x13 0x4 IRQ_TYPE_EDGE_BOTH>,
			     <0x0 0x12 0x2 IRQ_TYPE_EDGE_BOTH>,
			     <0x0 0x16 0x1 IRQ_TYPE_EDGE_RISING>,
			     <0x0 0x13 0x7 IRQ_TYPE_EDGE_RISING>;
		interrupt-names = "usbin-plugin", "bat-ov", "wdog-bark", "usbin-icl-change";

		io-channels = <&pm6150_adc ADC5_USB_IN_I>,
			      <&pm6150_adc ADC5_USB_IN_V_16>;
		io-channel-names = "usb_in_i_uv", "usb_in_v_div_16";

		monitored-battery = <&battery>;
	};
};

/*
 * Display: the real MDSS/DPU/DSI stack. The panel is a Samsung-style 1080x2400 AMOLED in video mode
 * (stock node qcom,mdss_dsi_k7_38_0c_0a_video); brightness is the DCS 0x51 command, which the panel driver
 * exposes as a backlight. The bootloader leaves the lab/ibb (LCDB) bias rails on and nothing here controls
 * them, so they are not listed. framebuffer0 stays until msm.ko takes the display over.
 *
 * Stock panel supplies: vddio = pm6150 L13 (1.8 V), vdda-3p3 = pm6150 L18 (3.0 V). The DSI host takes
 * vdda-1p2 = pm6150L L3 and the PHY vdda-0p9 = pm6150 L4.
 */
&tlmm {
	panel_reset_default: panel-reset-default-state {
		pins = "gpio91";
		function = "gpio";
		drive-strength = <8>;
		bias-disable;
	};
};

&mdss {
	status = "okay";
};

&mdss_mdp {
	status = "okay";
};

&mdss_dsi0 {
	vdda-supply = <&vreg_l3c>;
	status = "okay";

	panel@0 {
		compatible = "xiaomi,mojito-k7-panel";
		reg = <0>;

		vddio-supply = <&vreg_l13a>;
		vci-supply = <&vreg_l18a>;
		reset-gpios = <&tlmm 91 GPIO_ACTIVE_LOW>;

		pinctrl-0 = <&panel_reset_default>;
		pinctrl-names = "default";

		port {
			panel_in: endpoint {
				remote-endpoint = <&mdss_dsi0_out>;
			};
		};
	};
};

&mdss_dsi0_out {
	remote-endpoint = <&panel_in>;
	data-lanes = <0 1 2 3>;
};

&mdss_dsi0_phy {
	vdda-supply = <&vreg_l4a>;
	status = "okay";
};

/*
 * Modem (MPSS) and IPA. All values are from the stock tree (qcom,mss@4080000 pas-id 4,
 * qcom,smp2p-modem, the "modem" glink edge, qcom,ipa@1e00000 hw-ver 0x10); the layout follows the
 * Redmi Note 7 Pro port (github.com/VipinVIP/violet-sm6150-mainline), which runs the same SoC's
 * modem. talos.dtsi (QCS615) has no modem, so none of this exists upstream.
 * The modem does not start on its own (auto_boot = false for sm8150-mpss-pas): start it with
 * echo start > /sys/class/remoteproc/remoteprocN/state after rmtfs and pd-mapper are up.
 */
&soc {
	smp2p-mpss {
		compatible = "qcom,smp2p";
		qcom,smem = <435>, <428>;
		interrupts = <GIC_SPI 451 IRQ_TYPE_EDGE_RISING 0>;
		mboxes = <&apss_shared 14>;
		qcom,local-pid = <0>;
		qcom,remote-pid = <1>;

		mpss_smp2p_out: master-kernel {
			qcom,entry-name = "master-kernel";
			#qcom,smem-state-cells = <1>;
		};

		mpss_smp2p_in: slave-kernel {
			qcom,entry-name = "slave-kernel";
			interrupt-controller;
			#interrupt-cells = <2>;
		};

		/* used by the modem to report on the WLAN subsystem it hosts */
		mpss_smp2p_wlan_in: wlan {
			qcom,entry-name = "wlan";
			interrupt-controller;
			#interrupt-cells = <2>;
		};

		/* IPA clock query / setup-ready handshake */
		mpss_smp2p_ipa_out: ipa-ap-to-modem {
			qcom,entry-name = "ipa";
			#qcom,smem-state-cells = <1>;
		};

		mpss_smp2p_ipa_in: ipa-modem-to-ap {
			qcom,entry-name = "ipa";
			interrupt-controller;
			#interrupt-cells = <2>;
		};
	};

	/*
	 * IPA v4.2 (stock qcom,ipa-hw-ver = 0x10), the same as sc7180. Unlike the Redmi Note 7 Pro,
	 * this phone ships ipa_fws (stock qcom,ipa_fws node, PAS id 15), so the AP loads the GSI
	 * firmware into ipa-fw@97b00000 ("self"); with "modem" the modem never starts the handshake.
	 */
	ipa: ipa@1e40000 {
		compatible = "qcom,sc7180-ipa";
		reg = <0x0 0x01e40000 0x0 0x7000>,
		      <0x0 0x01e47000 0x0 0x2000>,
		      <0x0 0x01e04000 0x0 0x2c000>;
		reg-names = "ipa-reg", "ipa-shared", "gsi";

		iommus = <&apps_smmu 0x1520 0x0>,
			 <&apps_smmu 0x1522 0x0>;

		interrupts-extended = <&intc GIC_SPI 311 IRQ_TYPE_EDGE_RISING 0>,
				      <&intc GIC_SPI 432 IRQ_TYPE_LEVEL_HIGH 0>,
				      <&mpss_smp2p_ipa_in 0 IRQ_TYPE_EDGE_RISING>,
				      <&mpss_smp2p_ipa_in 1 IRQ_TYPE_EDGE_RISING>;
		interrupt-names = "ipa", "gsi", "ipa-clock-query", "ipa-setup-ready";

		clocks = <&rpmhcc RPMH_IPA_CLK>;
		clock-names = "core";

		interconnects = <&aggre1_noc MASTER_IPA QCOM_ICC_TAG_ALWAYS
				 &mc_virt SLAVE_EBI1 QCOM_ICC_TAG_ALWAYS>,
				<&aggre1_noc MASTER_IPA QCOM_ICC_TAG_ALWAYS
				 &system_noc SLAVE_IMEM QCOM_ICC_TAG_ALWAYS>,
				<&gem_noc MASTER_APPSS_PROC QCOM_ICC_TAG_ALWAYS
				 &config_noc SLAVE_IPA_CFG QCOM_ICC_TAG_ALWAYS>;
		interconnect-names = "memory", "imem", "config";

		qcom,qmp = <&aoss_qmp>;

		qcom,smem-states = <&mpss_smp2p_ipa_out 0>,
				   <&mpss_smp2p_ipa_out 1>;
		qcom,smem-state-names = "ipa-clock-enabled-valid",
					"ipa-clock-enabled";

		qcom,gsi-loader = "self";
		memory-region = <&ipa_fw_mem>;
		firmware-name = "postmarketos/ipa_fws.mdt";
	};

	remoteproc_mpss: remoteproc@4080000 {
		compatible = "qcom,sm8150-mpss-pas";
		reg = <0x0 0x04080000 0x0 0x4040>;

		interrupts-extended = <&intc GIC_SPI 266 IRQ_TYPE_EDGE_RISING 0>,
				      <&mpss_smp2p_in 0 IRQ_TYPE_EDGE_RISING>,
				      <&mpss_smp2p_in 1 IRQ_TYPE_EDGE_RISING>,
				      <&mpss_smp2p_in 2 IRQ_TYPE_EDGE_RISING>,
				      <&mpss_smp2p_in 3 IRQ_TYPE_EDGE_RISING>,
				      <&mpss_smp2p_in 7 IRQ_TYPE_EDGE_RISING>;
		interrupt-names = "wdog", "fatal", "ready", "handover", "stop-ack", "shutdown-ack";

		clocks = <&rpmhcc RPMH_CXO_CLK>;
		clock-names = "xo";

		power-domains = <&rpmhpd RPMHPD_CX>, <&rpmhpd RPMHPD_MSS>;	/* MSS: patch 0013 */
		power-domain-names = "cx", "mss";

		memory-region = <&mpss_mem>;

		pinctrl-names = "default";
		pinctrl-0 = <&cnss_wlan_en_active>;

		qcom,qmp = <&aoss_qmp>;

		qcom,smem-states = <&mpss_smp2p_out 0>;
		qcom,smem-state-names = "stop";

		firmware-name = "postmarketos/modem.mdt";

		glink-edge {
			interrupts-extended = <&intc GIC_SPI 449 IRQ_TYPE_EDGE_RISING 0>;
			mboxes = <&apss_shared 12>;
			label = "mpss";
			qcom,remote-pid = <1>;
		};
	};
};

/*
 * Wi-Fi: WCN3990 on SNOC (ath10k_snoc). Values from the stock qcom,icnss@18800000 node: SID 0x1640
 * (mask 1), CE interrupts SPI 414-425 (four interrupt cells on this GIC), the stock 2 MB wlan_msa_region
 * (the firmware asks for 0x4000 + 0x1fc000), supplies pm6150 L9 (cx-mx), pm6150l L1 (1.8 XO), L2 (1.3 RFA),
 * L10 (3.3 CH0), here routed through the upstream WCN3990 PMU / power-sequencing node below.
 * The WLAN firmware (wlanmdsp.mbn) is fetched by the modem from the phone through tqftpserv at modem boot.
 *
 * NOT WORKING, so disabled: the modem's WLAN service answers every request, but its first power-up
 * inside the capability request fails after ~200 ms (ath10k: "capability req rejected: 119"). Tested on
 * hardware without any change: rails and their order, GPIO 98 (see below), PMU/pwrseq, always-on rails,
 * MSA size and permissions (with and without qcom,msa-fixed-perm), host capability message variants,
 * VBATT_REQ, waiting for MSA_READY_IND, board data first, firmware build, writable file-based rmtfs.
 * See HANDOFF.md "Wi-Fi" for the whole investigation and what is left.
 */
/*
 * WLAN enable. The stock tree defines GPIO 98 as "cnss_wlan_en_active" (output-high, pull-up, 16 mA drive) and the
 * working Redmi Note 7 Pro port drives it high from kernel start; it reads low if left alone. A plain gpio-hog only
 * gave "out high, pull down, 2 mA", so use the exact stock pin state instead, bound to the modem node so it is applied
 * before the modem (and its WLAN process) starts.
 */
&tlmm {
	cnss_wlan_en_active: cnss-wlan-en-active-state {
		pins = "gpio98";
		function = "gpio";
		drive-strength = <16>;
		bias-pull-up;
		output-high;
	};
};

/*
 * WCN3990 PMU, the community way (upstream power sequencing, drivers/power/sequencing/pwrseq-qcom-wcn.c, used by
 * the SDM845 and SM8150 boards): it brings up VDD_IO first, then XO/RF/CH0/CH1, then waits 50 ms, and ath10k_snoc
 * powers the chip through it when its supplies come from this node. L10a stays always-on (see its comment).
 * No swctrl-gpios: the sw-ctrl pin of this SoC family was not found, and the driver does not read the property.
 */
/ {
	wcn3990-pmu {
		compatible = "qcom,wcn3990-pmu";

		vddio-supply = <&vreg_l10a>;
		vddxo-supply = <&vreg_l1c>;
		vddrf-supply = <&vreg_l2c>;
		vddch0-supply = <&vreg_l10c>;
		vddch1-supply = <&vreg_l11c>;

		regulators {
			vreg_pmu_io: ldo0 {
				regulator-name = "vreg_pmu_io";
			};

			vreg_pmu_xo: ldo1 {
				regulator-name = "vreg_pmu_xo";
			};

			vreg_pmu_rf: ldo2 {
				regulator-name = "vreg_pmu_rf";
			};

			vreg_pmu_ch0: ldo3 {
				regulator-name = "vreg_pmu_ch0";
			};

			vreg_pmu_ch1: ldo4 {
				regulator-name = "vreg_pmu_ch1";
			};
		};
	};
};

&soc {
	wifi@18800000 {
		compatible = "qcom,wcn3990-wifi";
		reg = <0x0 0x18800000 0x0 0x800000>;
		reg-names = "membase";

		iommus = <&apps_smmu 0x1640 0x1>;

		interrupts = <GIC_SPI 414 IRQ_TYPE_LEVEL_HIGH 0>,
			     <GIC_SPI 415 IRQ_TYPE_LEVEL_HIGH 0>,
			     <GIC_SPI 416 IRQ_TYPE_LEVEL_HIGH 0>,
			     <GIC_SPI 417 IRQ_TYPE_LEVEL_HIGH 0>,
			     <GIC_SPI 418 IRQ_TYPE_LEVEL_HIGH 0>,
			     <GIC_SPI 419 IRQ_TYPE_LEVEL_HIGH 0>,
			     <GIC_SPI 420 IRQ_TYPE_LEVEL_HIGH 0>,
			     <GIC_SPI 421 IRQ_TYPE_LEVEL_HIGH 0>,
			     <GIC_SPI 422 IRQ_TYPE_LEVEL_HIGH 0>,
			     <GIC_SPI 423 IRQ_TYPE_LEVEL_HIGH 0>,
			     <GIC_SPI 424 IRQ_TYPE_LEVEL_HIGH 0>,
			     <GIC_SPI 425 IRQ_TYPE_LEVEL_HIGH 0>;

		vdd-0.8-cx-mx-supply = <&vreg_l9a>;
		/* from the WCN3990 PMU node above (pwrseq), not straight from the PMIC rails */
		vdd-1.8-xo-supply = <&vreg_pmu_xo>;
		vdd-1.3-rfa-supply = <&vreg_pmu_rf>;
		vdd-3.3-ch0-supply = <&vreg_pmu_ch0>;

		memory-region = <&wlan_msa_mem>;

		vdd-3.3-ch1-supply = <&vreg_pmu_ch1>;

		/*
		 * Works once the ADSP sensor PD is served by hexagonrpcd; ath10k_snoc is blacklisted for
		 * autoload and loaded by the mojito-wifi service after that (see HANDOFF.md).
		 */
		status = "okay";
	};
};

/*
 * CPU speed steps. The cpufreq hardware table of this SM6150 offers 1017.6 and 1708.8 MHz (little)
 * and 2016, 2112 and 2208 MHz (big), which talos.dtsi (written for QCS615) lacks: qcom-cpufreq-hw
 * then rejects them ("Voltage update failed") and the CPUs stop at 1593.6 / 1900.8 MHz. Voltages
 * come from the hardware table; the bandwidth votes copy the nearest existing step.
 */
&cpu0_opp_table {
	opp-1017600000 {
		opp-hz = /bits/ 64 <1017600000>;
		opp-peak-kBps = <(451000 * 4) (806400 * 16)>;
	};

	opp-1708800000 {
		opp-hz = /bits/ 64 <1708800000>;
		opp-peak-kBps = <(1017000 * 4) (1363200 * 16)>;
	};
};

&cpu6_opp_table {
	opp-2016000000 {
		opp-hz = /bits/ 64 <2016000000>;
		opp-peak-kBps = <(1555000 * 4) (1363200 * 16)>;
	};

	opp-2112000000 {
		opp-hz = /bits/ 64 <2112000000>;
		opp-peak-kBps = <(1555000 * 4) (1363200 * 16)>;
	};

	opp-2208000000 {
		opp-hz = /bits/ 64 <2208000000>;
		opp-peak-kBps = <(1555000 * 4) (1363200 * 16)>;
	};

};

/*
 * CPU thermal throttling. talos.dtsi gives the CPU zones only a critical trip, so nothing slows
 * the CPUs before the 115 C shutdown. Passive trips as on sc7180; the zone-to-core mapping is the
 * stock one (cpuss-* sit in the little cluster, cpu-1-0/1 on cpu6, cpu-1-2/3 on cpu7). There is
 * one cooling device per cpufreq policy, so the zones map to cpu0 or cpu6.
 */

&{/thermal-zones/cpuss-0-thermal} {
	polling-delay-passive = <250>;

	trips {
		cpuss0_alert0: trip-point0 {
			temperature = <90000>;
			hysteresis = <2000>;
			type = "passive";
		};

		cpuss0_alert1: trip-point1 {
			temperature = <95000>;
			hysteresis = <2000>;
			type = "passive";
		};
	};

	cooling-maps {
		map0 {
			trip = <&cpuss0_alert0>;
			cooling-device = <&cpu0 THERMAL_NO_LIMIT THERMAL_NO_LIMIT>;
		};

		map1 {
			trip = <&cpuss0_alert1>;
			cooling-device = <&cpu0 THERMAL_NO_LIMIT THERMAL_NO_LIMIT>;
		};
	};
};

&{/thermal-zones/cpuss-1-thermal} {
	polling-delay-passive = <250>;

	trips {
		cpuss1_alert0: trip-point0 {
			temperature = <90000>;
			hysteresis = <2000>;
			type = "passive";
		};

		cpuss1_alert1: trip-point1 {
			temperature = <95000>;
			hysteresis = <2000>;
			type = "passive";
		};
	};

	cooling-maps {
		map0 {
			trip = <&cpuss1_alert0>;
			cooling-device = <&cpu0 THERMAL_NO_LIMIT THERMAL_NO_LIMIT>;
		};

		map1 {
			trip = <&cpuss1_alert1>;
			cooling-device = <&cpu0 THERMAL_NO_LIMIT THERMAL_NO_LIMIT>;
		};
	};
};

&{/thermal-zones/cpuss-2-thermal} {
	polling-delay-passive = <250>;

	trips {
		cpuss2_alert0: trip-point0 {
			temperature = <90000>;
			hysteresis = <2000>;
			type = "passive";
		};

		cpuss2_alert1: trip-point1 {
			temperature = <95000>;
			hysteresis = <2000>;
			type = "passive";
		};
	};

	cooling-maps {
		map0 {
			trip = <&cpuss2_alert0>;
			cooling-device = <&cpu0 THERMAL_NO_LIMIT THERMAL_NO_LIMIT>;
		};

		map1 {
			trip = <&cpuss2_alert1>;
			cooling-device = <&cpu0 THERMAL_NO_LIMIT THERMAL_NO_LIMIT>;
		};
	};
};

&{/thermal-zones/cpuss-3-thermal} {
	polling-delay-passive = <250>;

	trips {
		cpuss3_alert0: trip-point0 {
			temperature = <90000>;
			hysteresis = <2000>;
			type = "passive";
		};

		cpuss3_alert1: trip-point1 {
			temperature = <95000>;
			hysteresis = <2000>;
			type = "passive";
		};
	};

	cooling-maps {
		map0 {
			trip = <&cpuss3_alert0>;
			cooling-device = <&cpu0 THERMAL_NO_LIMIT THERMAL_NO_LIMIT>;
		};

		map1 {
			trip = <&cpuss3_alert1>;
			cooling-device = <&cpu0 THERMAL_NO_LIMIT THERMAL_NO_LIMIT>;
		};
	};
};

&{/thermal-zones/cpu-1-0-thermal} {
	polling-delay-passive = <250>;

	trips {
		cpu10_alert0: trip-point0 {
			temperature = <90000>;
			hysteresis = <2000>;
			type = "passive";
		};

		cpu10_alert1: trip-point1 {
			temperature = <95000>;
			hysteresis = <2000>;
			type = "passive";
		};
	};

	cooling-maps {
		map0 {
			trip = <&cpu10_alert0>;
			cooling-device = <&cpu6 THERMAL_NO_LIMIT THERMAL_NO_LIMIT>;
		};

		map1 {
			trip = <&cpu10_alert1>;
			cooling-device = <&cpu6 THERMAL_NO_LIMIT THERMAL_NO_LIMIT>;
		};
	};
};

&{/thermal-zones/cpu-1-1-thermal} {
	polling-delay-passive = <250>;

	trips {
		cpu11_alert0: trip-point0 {
			temperature = <90000>;
			hysteresis = <2000>;
			type = "passive";
		};

		cpu11_alert1: trip-point1 {
			temperature = <95000>;
			hysteresis = <2000>;
			type = "passive";
		};
	};

	cooling-maps {
		map0 {
			trip = <&cpu11_alert0>;
			cooling-device = <&cpu6 THERMAL_NO_LIMIT THERMAL_NO_LIMIT>;
		};

		map1 {
			trip = <&cpu11_alert1>;
			cooling-device = <&cpu6 THERMAL_NO_LIMIT THERMAL_NO_LIMIT>;
		};
	};
};

&{/thermal-zones/cpu-1-2-thermal} {
	polling-delay-passive = <250>;

	trips {
		cpu12_alert0: trip-point0 {
			temperature = <90000>;
			hysteresis = <2000>;
			type = "passive";
		};

		cpu12_alert1: trip-point1 {
			temperature = <95000>;
			hysteresis = <2000>;
			type = "passive";
		};
	};

	cooling-maps {
		map0 {
			trip = <&cpu12_alert0>;
			cooling-device = <&cpu6 THERMAL_NO_LIMIT THERMAL_NO_LIMIT>;
		};

		map1 {
			trip = <&cpu12_alert1>;
			cooling-device = <&cpu6 THERMAL_NO_LIMIT THERMAL_NO_LIMIT>;
		};
	};
};

&{/thermal-zones/cpu-1-3-thermal} {
	polling-delay-passive = <250>;

	trips {
		cpu13_alert0: trip-point0 {
			temperature = <90000>;
			hysteresis = <2000>;
			type = "passive";
		};

		cpu13_alert1: trip-point1 {
			temperature = <95000>;
			hysteresis = <2000>;
			type = "passive";
		};
	};

	cooling-maps {
		map0 {
			trip = <&cpu13_alert0>;
			cooling-device = <&cpu6 THERMAL_NO_LIMIT THERMAL_NO_LIMIT>;
		};

		map1 {
			trip = <&cpu13_alert1>;
			cooling-device = <&cpu6 THERMAL_NO_LIMIT THERMAL_NO_LIMIT>;
		};
	};
};
